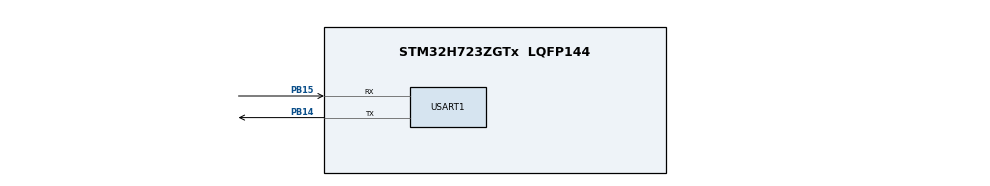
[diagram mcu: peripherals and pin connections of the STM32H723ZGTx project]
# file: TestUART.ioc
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Dma.Request0=USART1_RX
Dma.Request1=USART1_TX
Dma.USART1_RX.0.Direction=DMA_PERIPH_TO_MEMORY
Dma.USART1_RX.0.EventEnable=DISABLE
Dma.USART1_RX.0.FIFOMode=DMA_FIFOMODE_DISABLE
Dma.USART1_RX.0.Instance=DMA1_Stream0
Dma.USART1_RX.0.MemDataAlignment=DMA_MDATAALIGN_BYTE
Dma.USART1_RX.0.MemInc=DMA_MINC_ENABLE
Dma.USART1_RX.0.Mode=DMA_NORMAL
Dma.USART1_RX.0.PeriphDataAlignment=DMA_PDATAALIGN_BYTE
Dma.USART1_RX.0.PeriphInc=DMA_PINC_DISABLE
Dma.USART1_RX.0.Polarity=HAL_DMAMUX_REQ_GEN_RISING
Dma.USART1_RX.0.Priority=DMA_PRIORITY_LOW
Dma.USART1_RX.0.RequestNumber=1
Dma.USART1_RX.0.SignalID=NONE
Dma.USART1_RX.0.SyncEnable=DISABLE
Dma.USART1_RX.0.SyncPolarity=HAL_DMAMUX_SYNC_NO_EVENT
Dma.USART1_RX.0.SyncRequestNumber=1
Dma.USART1_RX.0.SyncSignalID=NONE
Dma.USART1_TX.1.Direction=DMA_MEMORY_TO_PERIPH
Dma.USART1_TX.1.EventEnable=DISABLE
Dma.USART1_TX.1.FIFOMode=DMA_FIFOMODE_DISABLE
Dma.USART1_TX.1.Instance=DMA1_Stream1
Dma.USART1_TX.1.MemDataAlignment=DMA_MDATAALIGN_BYTE
Dma.USART1_TX.1.MemInc=DMA_MINC_ENABLE
Dma.USART1_TX.1.Mode=DMA_NORMAL
Dma.USART1_TX.1.PeriphDataAlignment=DMA_PDATAALIGN_BYTE
Dma.USART1_TX.1.PeriphInc=DMA_PINC_DISABLE
Dma.USART1_TX.1.Polarity=HAL_DMAMUX_REQ_GEN_RISING
Dma.USART1_TX.1.Priority=DMA_PRIORITY_LOW
Dma.USART1_TX.1.RequestNumber=1
Dma.USART1_TX.1.SignalID=NONE
Dma.USART1_TX.1.SyncEnable=DISABLE
Dma.USART1_TX.1.SyncPolarity=HAL_DMAMUX_SYNC_NO_EVENT
Dma.USART1_TX.1.SyncRequestNumber=1
Dma.USART1_TX.1.SyncSignalID=NONE
Mcu.Family=STM32H7
Mcu.Name=STM32H723ZGTx
Mcu.Package=LQFP144
NVIC.DMA1_Stream0_IRQn=true\:0\:0\:false\:false\:true\:false\:true\:true
NVIC.DMA1_Stream1_IRQn=true\:0\:0\:false\:false\:true\:false\:true\:true
NVIC.PriorityGroup=NVIC_PRIORITYGROUP_4
NVIC.USART1_IRQn=true\:0\:0\:false\:false\:true\:true\:true\:true
PB14.Mode=Asynchronous
PB14.Signal=USART1_TX
PB15.Mode=Asynchronous
PB15.Signal=USART1_RX
ProjectManager.HeapSize=0x200
ProjectManager.StackSize=0x400
ProjectManager.TargetToolchain=STM32CubeIDE
RCC.ADCFreq_Value=129000000
RCC.APB1Freq_Value=32000000
RCC.APB2Freq_Value=32000000
RCC.APB3Freq_Value=32000000
RCC.APB4Freq_Value=32000000
RCC.CortexFreq_Value=64000000
RCC.D1PPRE=RCC_APB3_DIV2
RCC.D2PPRE1=RCC_APB1_DIV2
RCC.D2PPRE2=RCC_APB2_DIV2
RCC.D3PPRE=RCC_APB4_DIV2
RCC.HCLKFreq_Value=64000000
RCC.SYSCLKFreq_VALUE=64000000
RCC.USBFreq_Value=129000000
USART1.VirtualMode-Asynchronous=VM_ASYNC
board=custom

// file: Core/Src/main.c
/* USER CODE BEGIN Header */
/**
  ******************************************************************************
  * @file           : main.c
  * @brief          : Main program body
  ******************************************************************************
  * @attention
  *
  * Copyright (c) 2024 STMicroelectronics.
  * All rights reserved.
  *
  * This software is licensed under terms that can be found in the LICENSE file
  * in the root directory of this software component.
  * If no LICENSE file comes with this software, it is provided AS-IS.
  *
  ******************************************************************************
  */
/* USER CODE END Header */
#include "main.h"

/* USER CODE BEGIN PTD */
char rx_data[30];  // Buffer for incoming data (adjust size as needed)
float rx_angle1, rx_angle2, rx_angle3 = 0;
int receiveComplete;
/* USER CODE END PTD */

UART_HandleTypeDef huart1;
DMA_HandleTypeDef hdma_usart1_rx;
DMA_HandleTypeDef hdma_usart1_tx;

void SystemClock_Config(void);
static void MX_GPIO_Init(void);
static void MX_DMA_Init(void);
static void MX_USART1_UART_Init(void);

/* USER CODE BEGIN 0 */

void HAL_UART_RxCpltCallback(UART_HandleTypeDef *huart)
{
	if (huart->Instance == huart1.Instance)
	    {
	        // Ensure received data is null-terminated
	        rx_data[29] = '\0';

	        // Parse the received string using strtok
	        char *token = strtok(rx_data, ",");  // Split by comma
	        if (token != NULL) rx_angle1 = atof(token);

	        token = strtok(NULL, ",");
	        if (token != NULL) rx_angle2 = atof(token);

	        token = strtok(NULL, ",");
	        if (token != NULL) rx_angle3 = atof(token);

	        // Restart reception
	        HAL_UART_Receive_DMA(&huart1, (uint8_t *)rx_data, 29);  // Adjust size based on expected length
	        receiveComplete = 1;
	    }
}

/* USER CODE END 0 */

int main(void)
{

  /* MCU Configuration--------------------------------------------------------*/

  /* Reset of all peripherals, Initializes the Flash interface and the Systick. */
  HAL_Init();

  /* Configure the system clock */
  SystemClock_Config();

  /* Initialize all configured peripherals */
  MX_GPIO_Init();
  MX_DMA_Init();
  MX_USART1_UART_Init();
  /* USER CODE BEGIN 2 */
  HAL_UART_Receive_DMA(&huart1, (uint8_t *)rx_data, 29);
  /* USER CODE END 2 */

  /* Infinite loop */
  while (1)
  {

  }
}

void SystemClock_Config(void)
{
  RCC_OscInitTypeDef RCC_OscInitStruct = {0};
  RCC_ClkInitTypeDef RCC_ClkInitStruct = {0};

  /** Supply configuration update enable
  */
  HAL_PWREx_ConfigSupply(PWR_LDO_SUPPLY);

  /** Configure the main internal regulator output voltage
  */
  __HAL_PWR_VOLTAGESCALING_CONFIG(PWR_REGULATOR_VOLTAGE_SCALE3);

  while(!__HAL_PWR_GET_FLAG(PWR_FLAG_VOSRDY)) {}

  /** Initializes the RCC Oscillators according to the specified parameters
  * in the RCC_OscInitTypeDef structure.
  */
  RCC_OscInitStruct.OscillatorType = RCC_OSCILLATORTYPE_HSI;
  RCC_OscInitStruct.HSIState = RCC_HSI_DIV1;
  RCC_OscInitStruct.HSICalibrationValue = 64;
  RCC_OscInitStruct.PLL.PLLState = RCC_PLL_NONE;
  if (HAL_RCC_OscConfig(&RCC_OscInitStruct) != HAL_OK)
  {
    Error_Handler();
  }

  /** Initializes the CPU, AHB and APB buses clocks
  */
  RCC_ClkInitStruct.ClockType = RCC_CLOCKTYPE_HCLK|RCC_CLOCKTYPE_SYSCLK
                              |RCC_CLOCKTYPE_PCLK1|RCC_CLOCKTYPE_PCLK2
                              |RCC_CLOCKTYPE_D3PCLK1|RCC_CLOCKTYPE_D1PCLK1;
  RCC_ClkInitStruct.SYSCLKSource = RCC_SYSCLKSOURCE_HSI;
  RCC_ClkInitStruct.SYSCLKDivider = RCC_SYSCLK_DIV1;
  RCC_ClkInitStruct.AHBCLKDivider = RCC_HCLK_DIV1;
  RCC_ClkInitStruct.APB3CLKDivider = RCC_APB3_DIV2;
  RCC_ClkInitStruct.APB1CLKDivider = RCC_APB1_DIV2;
  RCC_ClkInitStruct.APB2CLKDivider = RCC_APB2_DIV2;
  RCC_ClkInitStruct.APB4CLKDivider = RCC_APB4_DIV2;

  if (HAL_RCC_ClockConfig(&RCC_ClkInitStruct, FLASH_LATENCY_1) != HAL_OK)
  {
    Error_Handler();
  }
}

static void MX_USART1_UART_Init(void)
{

  huart1.Instance = USART1;
  huart1.Init.BaudRate = 115200;
  huart1.Init.WordLength = UART_WORDLENGTH_8B;
  huart1.Init.StopBits = UART_STOPBITS_1;
  huart1.Init.Parity = UART_PARITY_NONE;
  huart1.Init.Mode = UART_MODE_TX_RX;
  huart1.Init.HwFlowCtl = UART_HWCONTROL_NONE;
  huart1.Init.OverSampling = UART_OVERSAMPLING_16;
  huart1.Init.OneBitSampling = UART_ONE_BIT_SAMPLE_DISABLE;
  huart1.Init.ClockPrescaler = UART_PRESCALER_DIV1;
  huart1.AdvancedInit.AdvFeatureInit = UART_ADVFEATURE_NO_INIT;
  if (HAL_UART_Init(&huart1) != HAL_OK)
  {
    Error_Handler();
  }
  if (HAL_UARTEx_SetTxFifoThreshold(&huart1, UART_TXFIFO_THRESHOLD_1_8) != HAL_OK)
  {
    Error_Handler();
  }
  if (HAL_UARTEx_SetRxFifoThreshold(&huart1, UART_RXFIFO_THRESHOLD_1_8) != HAL_OK)
  {
    Error_Handler();
  }
  if (HAL_UARTEx_DisableFifoMode(&huart1) != HAL_OK)
  {
    Error_Handler();
  }

}

static void MX_DMA_Init(void)
{

  /* DMA controller clock enable */
  __HAL_RCC_DMA1_CLK_ENABLE();

  /* DMA interrupt init */
  /* DMA1_Stream0_IRQn interrupt configuration */
  HAL_NVIC_SetPriority(DMA1_Stream0_IRQn, 0, 0);
  HAL_NVIC_EnableIRQ(DMA1_Stream0_IRQn);
  /* DMA1_Stream1_IRQn interrupt configuration */
  HAL_NVIC_SetPriority(DMA1_Stream1_IRQn, 0, 0);
  HAL_NVIC_EnableIRQ(DMA1_Stream1_IRQn);

}

static void MX_GPIO_Init(void)
{

  /* GPIO Ports Clock Enable */
  __HAL_RCC_GPIOB_CLK_ENABLE();

}

void Error_Handler(void)
{
  __disable_irq();
  while (1)
  {
  }
}
